VERSION "created by canmatrix"

NS_ :

BS_:

BU_:

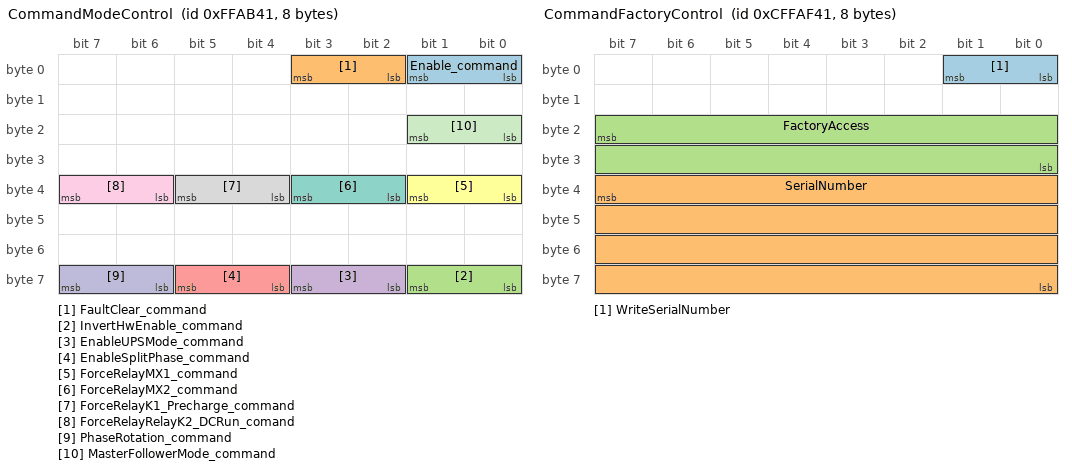
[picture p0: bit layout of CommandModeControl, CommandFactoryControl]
BO_ 16755521 CommandModeControl: 8 Vector__XXX
 SG_ Enable_command : 1|2@0+ (1,0) [0|1] "" Vector__XXX
 SG_ FaultClear_command : 3|2@0+ (1,0) [0|1] "" Vector__XXX
 SG_ InvertHwEnable_command : 57|2@0+ (1,0) [0|1] "" Vector__XXX
 SG_ EnableUPSMode_command : 59|2@0+ (1,0) [0|1] "" Vector__XXX
 SG_ EnableSplitPhase_command : 61|2@0+ (1,0) [0|1] "" Vector__XXX
 SG_ ForceRelayMX1_command : 33|2@0+ (1,0) [0|1] "" Vector__XXX
 SG_ ForceRelayMX2_command : 35|2@0+ (1,0) [0|1] "" Vector__XXX
 SG_ ForceRelayK1_Precharge_command : 37|2@0+ (1,0) [0|1] "" Vector__XXX
 SG_ ForceRelayRelayK2_DCRun_comand : 39|2@0+ (1,0) [0|1] "" Vector__XXX
 SG_ PhaseRotation_command : 63|2@0+ (1,0) [0|1] "" Vector__XXX
 SG_ MasterFollowerMode_command : 17|2@0+ (1,0) [0|1] "" Vector__XXX

BO_ 218082369 CommandPower: 8 Vector__XXX
 SG_ RealPower_command : 7|32@0+ (1,0) [-90000|90000] "W" Vector__XXX
 SG_ ReactivePower_command : 39|32@0+ (1,0) [-90000|90000] "VA" Vector__XXX

BO_ 218082881 CommandVF: 8 Vector__XXX
 SG_ Voltage_command : 7|16@0+ (0.1,0) [10|500] "Vrms" Vector__XXX
 SG_ Frequency_command : 23|16@0+ (0.1,0) [45|65] "Hz" Vector__XXX

BO_ 218090230 MasterMeasuredPower: 8 Vector__XXX
 SG_ RealPower_measured : 7|32@0+ (1,0) [0|1] "W" Vector__XXX
 SG_ ReactivePower_measured : 39|32@0+ (1,0) [0|1] "VA" Vector__XXX

BO_ 218083137 CommandFactoryControl: 8 Vector__XXX
 SG_ WriteSerialNumber : 1|2@0+ (1,0) [0|1] "" Vector__XXX
 SG_ SerialNumber : 39|32@0+ (1,0) [0|1] "" Vector__XXX
 SG_ FactoryAccess : 23|16@0+ (1,0) [0|1] "" Vector__XXX

BO_ 218081857 CommandSetNVParam: 8 Vector__XXX
 SG_ CommandSetNVParam_MUX M  : 7|16@1+ (1,0) [0|1] "" Vector__XXX
 SG_ Dummy m0  : 23|16@0+ (1,0) [0|1] "" Vector__XXX
 SG_ VUnder50pct m1  : 23|16@0+ (1,0) [1|30000] "ms" Vector__XXX
 SG_ V50to88pct m1  : 39|16@0+ (1,0) [1|30000] "ms" Vector__XXX
 SG_ V110to120pct m1  : 55|16@0+ (1,0) [1|30000] "ms" Vector__XXX
 SG_ VOver120 m2  : 23|16@0+ (1,0) [1|30000] "" Vector__XXX
 SG_ FreqHi m3  : 23|16@0+ (0.1,0) [40|70] "Hz" Vector__XXX
 SG_ FreqLo m3  : 39|16@0+ (0.1,0) [40|70] "Hz" Vector__XXX
 SG_ FreqVeryLo m3  : 55|16@0+ (0.1,0) [40|70] "Hz" Vector__XXX
 SG_ FreqVeryLo m4  : 23|16@0+ (1,0) [160|160] "ms" Vector__XXX
 SG_ FreqLo m4  : 39|16@0+ (1,0) [1|30000] "ms" Vector__XXX
 SG_ FreqHi m4  : 55|16@0+ (1,0) [160|160] "ms" Vector__XXX
 SG_ NodeID m5  : 23|8@0+ (1,0) [0|247] "" Vector__XXX
 SG_ SA_Mask m5  : 31|8@0+ (1,0) [0|1] "" Vector__XXX
 SG_ Baudrate m5  : 39|4@0+ (1,0) [0|3] "" Vector__XXX
 SG_ ThermalOverload m6  : 17|2@0+ (1,0) [0|1] "" Vector__XXX
 SG_ MX1Open m7  : 23|16@0+ (1,0) [0|5000] "ms" Vector__XXX
 SG_ MX1Close m7  : 39|16@0+ (1,0) [0|2000] "ms" Vector__XXX
 SG_ MX2Open m7  : 55|16@0+ (1,0) [0|1] "ms" Vector__XXX
 SG_ MX2Close m8  : 23|16@0+ (1,0) [0|2000] "ms" Vector__XXX
 SG_ K1Open m8  : 39|16@0+ (1,0) [0|2000] "ms" Vector__XXX
 SG_ K1Close m8  : 55|16@0+ (1,0) [0|2000] "ms" Vector__XXX
 SG_ K2Open m9  : 23|16@0+ (1,0) [0|2000] "ms" Vector__XXX
 SG_ K2Close m9  : 39|16@0+ (1,0) [0|2000] "ms" Vector__XXX

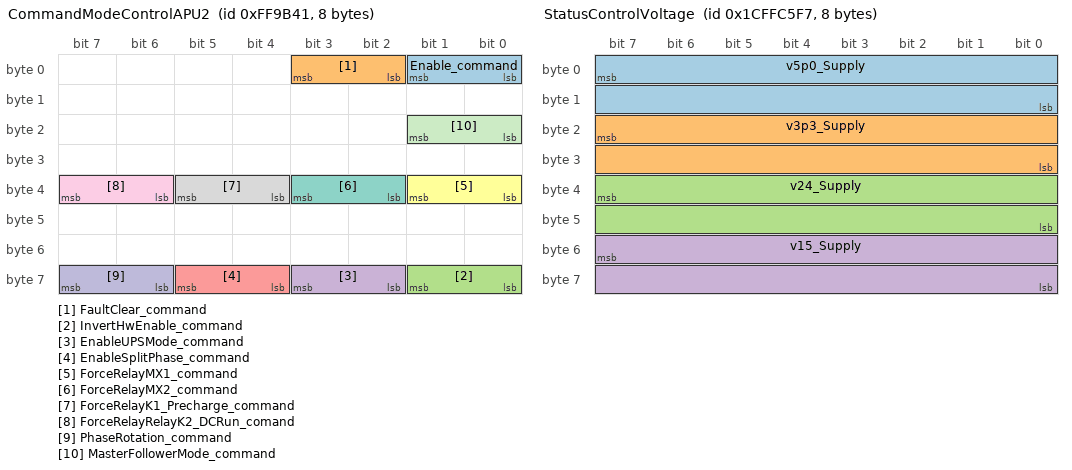
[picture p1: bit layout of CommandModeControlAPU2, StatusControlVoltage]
BO_ 16751425 CommandModeControlAPU2: 8 Vector__XXX
 SG_ Enable_command : 1|2@0+ (1,0) [0|1] "" Vector__XXX
 SG_ FaultClear_command : 3|2@0+ (1,0) [0|1] "" Vector__XXX
 SG_ InvertHwEnable_command : 57|2@0+ (1,0) [0|1] "" Vector__XXX
 SG_ EnableUPSMode_command : 59|2@0+ (1,0) [0|1] "" Vector__XXX
 SG_ EnableSplitPhase_command : 61|2@0+ (1,0) [0|1] "" Vector__XXX
 SG_ ForceRelayMX1_command : 33|2@0+ (1,0) [0|1] "" Vector__XXX
 SG_ ForceRelayMX2_command : 35|2@0+ (1,0) [0|1] "" Vector__XXX
 SG_ ForceRelayK1_Precharge_command : 37|2@0+ (1,0) [0|1] "" Vector__XXX
 SG_ ForceRelayRelayK2_DCRun_comand : 39|2@0+ (1,0) [0|1] "" Vector__XXX
 SG_ PhaseRotation_command : 63|2@0+ (1,0) [0|1] "" Vector__XXX
 SG_ MasterFollowerMode_command : 17|2@0+ (1,0) [0|1] "" Vector__XXX

BO_ 218078273 CommandPowerAPU2: 8 Vector__XXX
 SG_ RealPower_command : 7|32@0+ (1,0) [-90000|90000] "W" Vector__XXX
 SG_ ReactivePower_command : 39|32@0+ (1,0) [-90000|90000] "VA" Vector__XXX

BO_ 218078785 CommandVFAPU2: 8 Vector__XXX
 SG_ Voltage_command : 7|16@0+ (0.1,0) [10|500] "Vrms" Vector__XXX
 SG_ Frequency_command : 23|16@0+ (0.1,0) [45|65] "Hz" Vector__XXX

BO_ 218090231 MasterMeasuredPowerAPU2: 8 Vector__XXX
 SG_ RealPower_measured : 7|32@0+ (1,0) [0|1] "W" Vector__XXX
 SG_ ReactivePower_measured : 39|32@0+ (1,0) [0|1] "VA" Vector__XXX

BO_ 218090231 StatusMeasuredPower: 8 Vector__XXX
 SG_ RealPower_measured : 7|32@0+ (1,0) [0|1] "W" Vector__XXX
 SG_ ReactivePower_measured : 39|32@0+ (1,0) [0|1] "VA" Vector__XXX

BO_ 419415287 StatusCommandedPower: 8 Vector__XXX
 SG_ RealPower_echo : 7|32@0+ (1,0) [0|1] "W" Vector__XXX
 SG_ ReactivePower_echo : 39|32@0+ (1,0) [0|1] "VA" Vector__XXX

BO_ 218088439 StatusBits: 8 Vector__XXX
 SG_ State_status : 3|4@0+ (1,0) [0|7] "" Vector__XXX
 SG_ MX2Permissive_status : 19|2@0+ (1,0) [0|1] "" Vector__XXX
 SG_ PowerAvailAC_status : 11|2@0+ (1,0) [0|1] "" Vector__XXX
 SG_ PowerAvailDC_status : 13|2@0+ (1,0) [0|1] "" Vector__XXX
 SG_ PowerCircuitEnabled_status : 15|2@0+ (1,0) [0|1] "" Vector__XXX
 SG_ HardwareEnable_status : 9|2@0+ (1,0) [0|1] "" Vector__XXX
 SG_ Enable_echo : 5|2@0+ (1,0) [0|1] "" Vector__XXX
 SG_ FaultClr_echo : 7|2@0+ (1,0) [0|1] "" Vector__XXX
 SG_ MessageValidModeControl_status : 25|2@0+ (1,0) [0|1] "" Vector__XXX
 SG_ MX1Permissive_status : 17|2@0+ (1,0) [0|1] "" Vector__XXX
 SG_ K2DCRunPermissive_status : 23|2@0+ (1,0) [0|1] "" Vector__XXX
 SG_ K1PrechargePermissive_status : 21|2@0+ (1,0) [0|1] "" Vector__XXX
 SG_ MessageValidPowerCMD_status : 27|2@0+ (1,0) [0|1] "" Vector__XXX
 SG_ MessageValidVF_status : 29|2@0+ (1,0) [0|1] "" Vector__XXX
 SG_ CANbus_status : 31|2@0+ (1,0) [0|1] "" Vector__XXX
 SG_ EnableUPSMode_echo : 33|2@0+ (1,0) [0|1] "" Vector__XXX
 SG_ EnableSplitPhase_echo : 35|2@0+ (1,0) [0|1] "" Vector__XXX
 SG_ PhaseRotation_status : 37|2@0+ (1,0) [0|1] "" Vector__XXX
 SG_ LineVoltageDetected_status : 39|2@0+ (1,0) [0|1] "" Vector__XXX
 SG_ PhaseRotation_echo : 41|2@0+ (1,0) [0|1] "" Vector__XXX

BO_ 486524407 StatusControlVoltage: 8 Vector__XXX
 SG_ v5p0_Supply : 7|16@0+ (0.01,0) [0|1] "V" Vector__XXX
 SG_ v3p3_Supply : 23|16@0+ (0.01,0) [0|1] "V" Vector__XXX
 SG_ v24_Supply : 39|16@0+ (0.01,0) [0|1] "V" Vector__XXX
 SG_ v15_Supply : 55|16@0+ (0.01,0) [0|1] "V" Vector__XXX

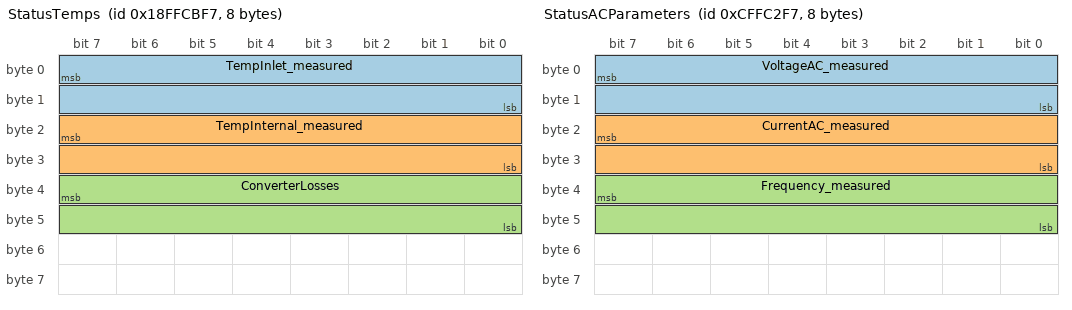
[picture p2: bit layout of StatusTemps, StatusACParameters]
BO_ 419417079 StatusTemps: 8 Vector__XXX
 SG_ TempInlet_measured : 7|16@0+ (0.1,0) [0|1] "C" Vector__XXX
 SG_ TempInternal_measured : 23|16@0+ (0.1,0) [0|1] "C" Vector__XXX
 SG_ ConverterLosses : 39|16@0+ (1,0) [0|1] "W" Vector__XXX

BO_ 218089719 StatusFaults: 8 Vector__XXX
 SG_ BridgeAVoltageOk_status : 59|1@0+ (1,0) [0|1] "" Vector__XXX
 SG_ OvercurrentAC_status : 3|2@0+ (1,0) [0|1] "" Vector__XXX
 SG_ BridgeBVoltageOk_status : 43|1@0+ (1,0) [0|1] "" Vector__XXX
 SG_ OvervoltageDC_status : 9|2@0+ (1,0) [0|1] "" Vector__XXX
 SG_ OvertempPowerDevice_status : 15|2@0+ (1,0) [0|1] "" Vector__XXX
 SG_ OvertempInternal_status : 13|2@0+ (1,0) [0|1] "" Vector__XXX
 SG_ LossValidControlMessage_status : 23|4@0+ (1,0) [0|1] "" Vector__XXX
 SG_ UndervoltageDC_status : 11|2@0+ (1,0) [0|1] "" Vector__XXX
 SG_ ControlHardwareFail_status : 19|4@0+ (1,0) [0|1] "" Vector__XXX
 SG_ OvercurrentDC_status : 7|2@0+ (1,0) [0|1] "" Vector__XXX
 SG_ GeneralFault_status : 1|2@0+ (1,0) [0|1] "" Vector__XXX
 SG_ LossOfAC_status : 5|2@0+ (1,0) [0|1] "" Vector__XXX
 SG_ EStopShutdown_status : 25|2@0+ (1,0) [0|1] "" Vector__XXX
 SG_ BridgeAFault_status : 58|3@0+ (1,0) [0|1] "" Vector__XXX
 SG_ BridgeBFault_status : 42|3@0+ (1,0) [0|1] "" Vector__XXX
 SG_ IllegalTransition_status : 27|2@0+ (1,0) [0|1] "" Vector__XXX
 SG_ InvalidEEHeader_status : 29|2@0+ (1,0) [0|1] "" Vector__XXX
 SG_ InvalidEESection_status : 31|2@0+ (1,0) [0|1] "" Vector__XXX
 SG_ ThermalOverload : 33|2@0+ (1,0) [0|1] "" Vector__XXX

BO_ 218088183 StatusACParameters: 8 Vector__XXX
 SG_ VoltageAC_measured : 7|16@0+ (0.1,0) [0|1] "V" Vector__XXX
 SG_ CurrentAC_measured : 23|16@0+ (1,0) [0|1] "A" Vector__XXX
 SG_ Frequency_measured : 39|16@0+ (0.1,0) [0|1] "Hz" Vector__XXX

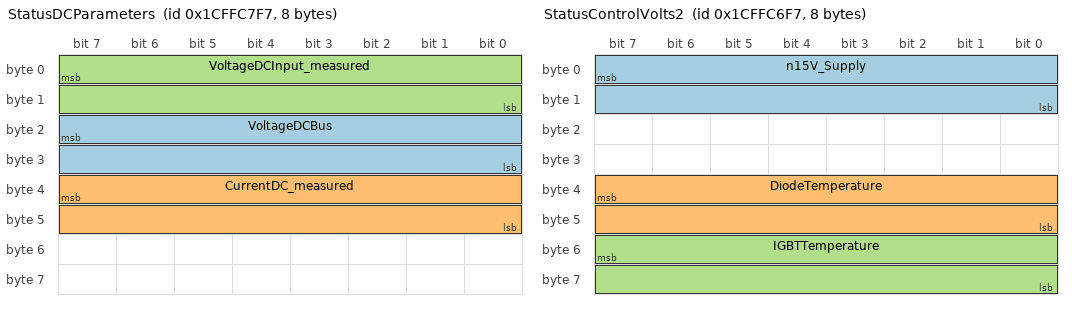
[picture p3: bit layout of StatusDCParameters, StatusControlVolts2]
BO_ 486524919 StatusDCParameters: 8 Vector__XXX
 SG_ VoltageDCBus : 23|16@0+ (1,0) [0|1] "V" Vector__XXX
 SG_ CurrentDC_measured : 39|16@0+ (1,0) [0|1] "A" Vector__XXX
 SG_ VoltageDCInput_measured : 7|16@0+ (1,0) [0|1] "V" Vector__XXX

BO_ 486524663 StatusControlVolts2: 8 Vector__XXX
 SG_ n15V_Supply : 7|16@0+ (0.01,0) [0|1] "V" Vector__XXX
 SG_ DiodeTemperature : 39|16@0+ (1,0) [0|1] "C" Vector__XXX
 SG_ IGBTTemperature : 55|16@0+ (1,0) [0|1] "C" Vector__XXX

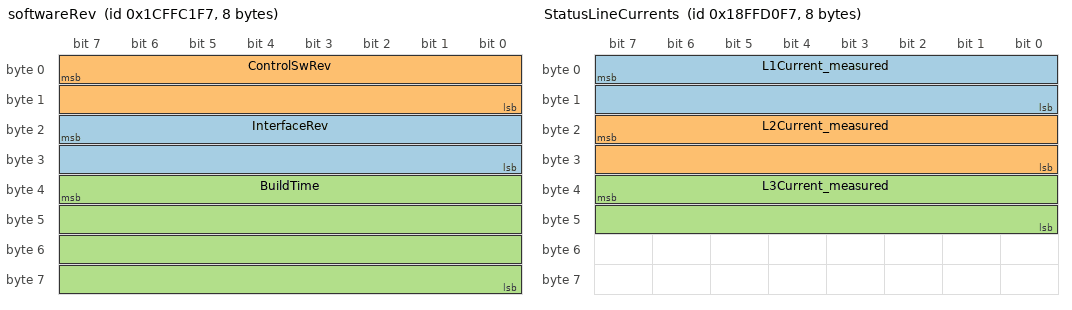
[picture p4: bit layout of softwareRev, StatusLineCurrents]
BO_ 486523383 softwareRev: 8 Vector__XXX
 SG_ InterfaceRev : 23|16@0+ (0.01,0) [0|1] "" Vector__XXX
 SG_ ControlSwRev : 7|16@0+ (0.01,0) [0|1] "" Vector__XXX
 SG_ BuildTime : 39|32@0+ (1,0) [0|1] "" Vector__XXX

BO_ 419416567 StatusCommandVF: 8 Vector__XXX
 SG_ Voltage_echo : 7|16@0+ (0.1,0) [0|1] "Vrms" Vector__XXX
 SG_ Frequency_echo : 23|16@0+ (0.1,0) [0|1] "Hz" Vector__XXX

BO_ 486526199 serialNumber: 8 Vector__XXX
 SG_ SerialNumber : 7|32@0+ (1,0) [0|1] "" Vector__XXX

BO_ 486526455 softwareRevHash: 8 Vector__XXX
 SG_ Hash : 7|28@0+ (1,0) [0|1] "" Vector__XXX

BO_ 486517239 StatusNVParam: 8 Vector__XXX
 SG_ StatusNVParam_MUX M  : 7|16@1+ (1,0) [0|1] "" Vector__XXX
 SG_ Dummy m0  : 23|16@0+ (1,0) [5|10] "" Vector__XXX
 SG_ VUnder50pct m1  : 23|16@0+ (1,0) [1|30000] "ms" Vector__XXX
 SG_ V50to88pct m1  : 39|16@0+ (1,0) [1|30000] "ms" Vector__XXX
 SG_ V110to120pct m1  : 55|16@0+ (1,0) [1|30000] "ms" Vector__XXX
 SG_ VOver120 m2  : 23|16@0+ (1,0) [1|30000] "" Vector__XXX
 SG_ FreqHi m3  : 23|16@0+ (0.1,0) [40|70] "Hz" Vector__XXX
 SG_ FreqLo m3  : 39|16@0+ (0.1,0) [40|70] "Hz" Vector__XXX
 SG_ FreqVeryLo m3  : 55|16@0+ (0.1,0) [40|70] "Hz" Vector__XXX
 SG_ FreqVeryLo m4  : 23|16@0+ (1,0) [160|160] "ms" Vector__XXX
 SG_ FreqLo m4  : 39|16@0+ (1,0) [1|30000] "ms" Vector__XXX
 SG_ FreqHi m4  : 55|16@0+ (1,0) [160|160] "ms" Vector__XXX
 SG_ StatusNodeID m5  : 23|8@0+ (1,0) [0|247] "" Vector__XXX
 SG_ StatusSA_Mask m5  : 31|8@0+ (1,0) [0|1] "" Vector__XXX
 SG_ StatusBaudrate m5  : 39|4@0+ (1,0) [0|3] "" Vector__XXX
 SG_ StatusThermalOverload m6  : 17|2@0+ (1,0) [0|1] "" Vector__XXX
 SG_ StatusMX1Open m7  : 23|16@0+ (1,0) [0|5000] "ms" Vector__XXX
 SG_ StatusMX1Close m7  : 39|16@0+ (1,0) [0|2000] "ms" Vector__XXX
 SG_ StatusMX2Open m7  : 55|16@0+ (1,0) [0|1] "ms" Vector__XXX
 SG_ StatusMX2Close m8  : 23|16@0+ (1,0) [0|2000] "ms" Vector__XXX
 SG_ StatusK1Open m8  : 39|16@0+ (1,0) [0|2000] "ms" Vector__XXX
 SG_ StatusK1Close m8  : 55|16@0+ (1,0) [0|2000] "ms" Vector__XXX
 SG_ StatusK2Open m9  : 23|16@0+ (1,0) [0|2000] "ms" Vector__XXX
 SG_ StatusK2Close m9  : 39|16@0+ (1,0) [0|2000] "ms" Vector__XXX

BO_ 419418359 StatusLineCurrents: 8 Vector__XXX
 SG_ L1Current_measured : 7|16@0+ (1,0) [0|1] "A" Vector__XXX
 SG_ L2Current_measured : 23|16@0+ (1,0) [0|1] "A" Vector__XXX
 SG_ L3Current_measured : 39|16@0+ (1,0) [0|1] "A" Vector__XXX

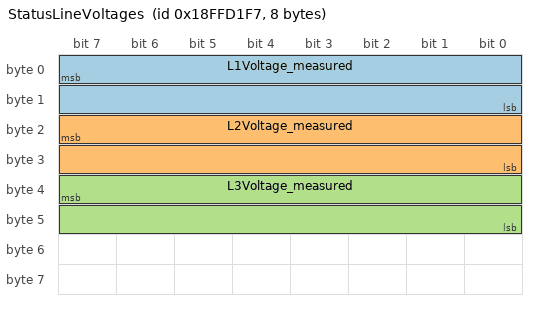
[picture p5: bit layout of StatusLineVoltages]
BO_ 419418615 StatusLineVoltages: 8 Vector__XXX
 SG_ L1Voltage_measured : 7|16@0+ (0.1,0) [0|1] "Vrms" Vector__XXX
 SG_ L2Voltage_measured : 23|16@0+ (0.1,0) [0|1] "Vrms" Vector__XXX
 SG_ L3Voltage_measured : 39|16@0+ (0.1,0) [0|1] "Vrms" Vector__XXX

CM_ BO_ 16755521  "Operational commands are received by the module via control bits within this message.";
CM_ BO_ 218082369  "Sets the desired real (P) and reactive (Q) power levels for the module to follow while in the GRID FOLLOWING mode.";
CM_ BO_ 218082881  "Sets the desired voltage and frequency for the module to produce while in the GRID FORMING mode.  In addition, while in the READY and GRID FOLLOWING modes, this message is used to set the nominal voltage levels for detection of acceptable AC line voltage.";
CM_ BO_ 218090230  "Returns the actual measured power.";
CM_ BO_ 218081857  "Provides access to configure non-volatile parameters.  Note that these parameters can only be set when the inverter's power stage is disabled (PowerCircuitEnabled_status in StatusBits message is 'Disabled.')";
CM_ BO_ 16751425  "Operational commands are received by the module via control bits within this message.";
CM_ BO_ 218078273  "Sets the desired real (P) and reactive (Q) power levels for the module to follow while in the GRID FOLLOWING mode.";
CM_ BO_ 218078785  "Sets the desired voltage and frequency for the module to produce while in the GRID FORMING mode.  In addition, while in the READY and GRID FOLLOWING modes, this message is used to set the nominal voltage levels for detection of acceptable AC line voltage.";
CM_ BO_ 218090231  "Returns the actual measured power.";
CM_ BO_ 218090231  "Returns the actual measured power.";
CM_ BO_ 419415287  "Echoes the commanded power (P&Q) as received in CommandPQ.";
CM_ BO_ 218088439  "Bits representing the status of the power module.";
CM_ BO_ 486524407  "Lists present voltage of each power supply on the control board (24V, 15V, 5V, and 3.3V.)";
CM_ BO_ 419417079  "Returns the inlet water temperature to the module as well as module internal ambient temperature.";
CM_ BO_ 218089719  "Fault bits.";
CM_ BO_ 218088183  "RMS AC Voltage, current, and frequency measured by line A, B and C feedbacks.";
CM_ BO_ 486524919  "Measured (boosted) DC Bus voltage, DC Current, and estimated DC Input voltage.";
CM_ BO_ 486524663  "Present voltage of the -15V power supply on the control board.";
CM_ BO_ 486523383  "Software revision.";
CM_ BO_ 419416567  "Echoes the voltage and frequency commands from commandVF.";
CM_ BO_ 486526199  "Serial number of the power module.";
CM_ BO_ 486526455  "Unique software revision identification hashcode.";
CM_ BO_ 486517239  "Echos back parameter values.";
CM_ BO_ 419418359  "Measured RMS line currents.";
CM_ BO_ 419418615  "Measured RMS line voltages.";

BA_DEF_ BO_ "GenMsgCycleTime" INT 0 65535;

BA_ "GenMsgCycleTime" BO_ 218090231 100;
BA_ "GenMsgCycleTime" BO_ 419415287 100;
BA_ "GenMsgCycleTime" BO_ 218088439 100;
BA_ "GenMsgCycleTime" BO_ 486524407 100;
BA_ "GenMsgCycleTime" BO_ 419417079 100;
BA_ "GenMsgCycleTime" BO_ 218089719 100;
BA_ "GenMsgCycleTime" BO_ 218088183 100;
BA_ "GenMsgCycleTime" BO_ 486524919 100;
BA_ "GenMsgCycleTime" BO_ 486524663 100;
BA_ "GenMsgCycleTime" BO_ 419416567 100;
BA_ "GenMsgCycleTime" BO_ 419418359 100;
BA_ "GenMsgCycleTime" BO_ 419418615 100;

VAL_ 16755521 Enable_command 0 "Disable" 1 "Enable" 2 "Error" 3 "N/A";
VAL_ 16755521 FaultClear_command 0 "Normal" 1 "Clear Faults" 2 "Error" 3 "N/A";
VAL_ 16755521 InvertHwEnable_command 0 "No invert" 1 "Invert" 2 "Error" 3 "N/A";
VAL_ 16755521 EnableUPSMode_command 0 "Disable" 1 "Enable" 2 "Error" 3 "N/A";
VAL_ 16755521 EnableSplitPhase_command 0 "Normal - Three Phase Mode" 1 "Enable Split Phase Mode" 2 "Error" 3 "N/A";
VAL_ 16755521 ForceRelayMX1_command 0 "Normal" 1 "Force On" 2 "Error" 3 "N/A";
VAL_ 16755521 ForceRelayMX2_command 0 "Normal" 1 "Force On" 2 "Error" 3 "N/A";
VAL_ 16755521 ForceRelayK1_Precharge_command 0 "Normal" 1 "Force On" 2 "Error" 3 "N/A";
VAL_ 16755521 ForceRelayRelayK2_DCRun_comand 0 "Normal" 1 "Force On" 2 "Error" 3 "N/A";
VAL_ 16755521 PhaseRotation_command 0 "Negative" 1 "Positive" 2 "Error" 3 "N/A";
VAL_ 16755521 MasterFollowerMode_command 0 "Master" 1 "Follower" 2 "Error" 3 "N/A";
VAL_ 218083137 WriteSerialNumber 0 "Disable" 1 "Enable" 2 "Error" 3 "N/A";
VAL_ 218081857 CommandSetNVParam_MUX 0 "Param0" 1 "LVM_ClearingTimes1" 2 "LVM_ClearingTimes2" 3 "LFM_Limits" 4 "LFM_ClearingTimes" 5 "J1939_Interface" 6 "Fault_Config" 7 "ContactorDelays1" 8 "ContactorDelays2" 9 "ContactorDelays3";
VAL_ 218081857 Baudrate 0 "125K" 1 "250K" 2 "500K" 3 "1M";
VAL_ 218081857 ThermalOverload 0 "Warning" 1 "Fault" 2 "Error" 3 "N/A";
VAL_ 16751425 Enable_command 0 "Disable" 1 "Enable" 2 "Error" 3 "N/A";
VAL_ 16751425 FaultClear_command 0 "Normal" 1 "Clear Faults" 2 "Error" 3 "N/A";
VAL_ 16751425 InvertHwEnable_command 0 "No invert" 1 "Invert" 2 "Error" 3 "N/A";
VAL_ 16751425 EnableUPSMode_command 0 "Disable" 1 "Enable" 2 "Error" 3 "N/A";
VAL_ 16751425 EnableSplitPhase_command 0 "Normal - Three Phase Mode" 1 "Enable Split Phase Mode" 2 "Error" 3 "N/A";
VAL_ 16751425 ForceRelayMX1_command 0 "Normal" 1 "Force On" 2 "Error" 3 "N/A";
VAL_ 16751425 ForceRelayMX2_command 0 "Normal" 1 "Force On" 2 "Error" 3 "N/A";
VAL_ 16751425 ForceRelayK1_Precharge_command 0 "Normal" 1 "Force On" 2 "Error" 3 "N/A";
VAL_ 16751425 ForceRelayRelayK2_DCRun_comand 0 "Normal" 1 "Force On" 2 "Error" 3 "N/A";
VAL_ 16751425 PhaseRotation_command 0 "Negative" 1 "Positive" 2 "Error" 3 "N/A";
VAL_ 16751425 MasterFollowerMode_command 0 "Master" 1 "Follower" 2 "Error" 3 "N/A";
VAL_ 218088439 State_status 0 "Power On Reset" 1 "Ready" 2 "Following" 3 "Fault" 4 "Forming" 5 "N/A" 6 "N/A" 7 "N/A" 8 "N/A" 9 "N/A" 10 "N/A" 11 "N/A" 12 "N/A" 13 "N/A" 14 "N/A" 15 "N/A";
VAL_ 218088439 MX2Permissive_status 0 "Open" 1 "Closed" 2 "Error" 3 "N/A";
VAL_ 218088439 PowerAvailAC_status 0 "None" 1 "Available" 2 "Error" 3 "N/A";
VAL_ 218088439 PowerAvailDC_status 0 "None" 1 "Available" 2 "Error" 3 "N/A";
VAL_ 218088439 PowerCircuitEnabled_status 0 "Disabled" 1 "Enabled" 2 "Error" 3 "N/A";
VAL_ 218088439 HardwareEnable_status 0 "Not Active" 1 "Active" 2 "Error" 3 "N/A";
VAL_ 218088439 Enable_echo 0 "Disable" 1 "Enable" 2 "Error" 3 "N/A";
VAL_ 218088439 FaultClr_echo 0 "Normal" 1 "Clear Faults" 2 "Error" 3 "N/A";
VAL_ 218088439 MessageValidModeControl_status 0 "Invalid" 1 "Valid" 2 "Error" 3 "N/A";
VAL_ 218088439 MX1Permissive_status 0 "Open" 1 "Closed" 2 "Error" 3 "N/A";
VAL_ 218088439 K2DCRunPermissive_status 0 "Open" 1 "Closed" 2 "Error" 3 "N/A";
VAL_ 218088439 K1PrechargePermissive_status 0 "Open" 1 "Closed" 2 "Error" 3 "N/A";
VAL_ 218088439 MessageValidPowerCMD_status 0 "Invalid" 1 "Valid" 2 "Error" 3 "N/A";
VAL_ 218088439 MessageValidVF_status 0 "Invalid" 1 "Valid" 2 "Error" 3 "N/A";
VAL_ 218088439 CANbus_status 0 "Normal" 1 "Warning" 3 "ErrorPassive" 4 "N/A";
VAL_ 218088439 EnableUPSMode_echo 0 "Disable" 1 "Enable" 2 "Error" 3 "N/A";
VAL_ 218088439 EnableSplitPhase_echo 0 "Normal - Three Phase Mode" 1 "Enable Split Phase Mode" 2 "Error" 3 "N/A";
VAL_ 218088439 PhaseRotation_status 0 "Negative" 1 "Positive" 2 "Error" 3 "N/A";
VAL_ 218088439 LineVoltageDetected_status 0 "No_Voltage" 1 "Voltage_Detected" 2 "Error" 3 "N/A";
VAL_ 218088439 PhaseRotation_echo 0 "Negative" 1 "Positive" 2 "Error" 3 "N/A";
VAL_ 218089719 BridgeAVoltageOk_status 0 "Normal" 1 "Fault Active" 2 "Error" 3 "N/A";
VAL_ 218089719 OvercurrentAC_status 0 "Normal" 1 "Fault Active" 2 "Error" 3 "N/A";
VAL_ 218089719 BridgeBVoltageOk_status 0 "Normal" 1 "Fault Active" 2 "Error" 3 "N/A";
VAL_ 218089719 OvervoltageDC_status 0 "Normal" 1 "Fault Active" 2 "Error" 3 "N/A";
VAL_ 218089719 OvertempPowerDevice_status 0 "Normal" 1 "Fault Active" 2 "Error" 3 "N/A";
VAL_ 218089719 OvertempInternal_status 0 "Normal" 1 "Fault Active" 2 "Error" 3 "N/A";
VAL_ 218089719 LossValidControlMessage_status 0 "Normal" 1 "Fault Active" 2 "Error" 3 "N/A";
VAL_ 218089719 UndervoltageDC_status 0 "Normal" 1 "Fault Active" 2 "Error" 3 "N/A";
VAL_ 218089719 ControlHardwareFail_status 0 "Normal" 1 "Fault Active" 2 "Error" 3 "N/A";
VAL_ 218089719 OvercurrentDC_status 0 "Normal" 1 "Fault Active" 2 "Error" 3 "N/A";
VAL_ 218089719 GeneralFault_status 0 "Normal" 1 "Fault Active" 2 "Error" 3 "N/A";
VAL_ 218089719 LossOfAC_status 0 "Normal" 1 "Fault Active" 2 "Error" 3 "N/A";
VAL_ 218089719 EStopShutdown_status 0 "Normal" 1 "Fault Active" 2 "Error" 3 "N/A";
VAL_ 218089719 BridgeAFault_status 0 "Normal" 1 "FLT_A" 2 "N/A" 3 "FLT_C" 4 "OverVoltage" 5 "FLT_B" 6 "Overcurrent" 7 "5V";
VAL_ 218089719 BridgeBFault_status 0 "Normal" 1 "FLT_A" 2 "N/A" 3 "FLT_C" 4 "OverVoltage" 5 "FLT_B" 6 "Overcurrent" 7 "5V";
VAL_ 218089719 IllegalTransition_status 0 "Normal" 1 "Fault Active" 2 "Error" 3 "N/A";
VAL_ 218089719 InvalidEEHeader_status 0 "Normal" 1 "Fault Active" 2 "Error" 3 "N/A";
VAL_ 218089719 InvalidEESection_status 0 "Normal" 1 "Fault Active" 2 "Error" 3 "N/A";
VAL_ 218089719 ThermalOverload 0 "Normal" 1 "Fault Active" 2 "Error" 3 "N/A";
VAL_ 486517239 StatusNVParam_MUX 0 "ActParam0" 1 "ActLVM_ClearingTimes1" 2 "ActLVM_ClearingTimes2" 3 "ActLFM_Limits" 4 "ActLFM_ClearingTimes" 5 "StatusJ1939_Interface" 6 "StatusFault_Config" 7 "StatusContactorDelays1" 8 "StatusContactorDelays2" 9 "StatusContactorDelays3";
VAL_ 486517239 StatusBaudrate 0 "125K" 1 "250K" 2 "500K" 3 "1M";
VAL_ 486517239 StatusThermalOverload 0 "Warning" 1 "Fault" 2 "Error" 3 "N/A";
